CM_ "IMPORT _honda_common.dbc";
CM_ "IMPORT _nidec_common.dbc";
CM_ "IMPORT _steering_sensors_b.dbc";
CM_ "IMPORT _steering_control_a.dbc";

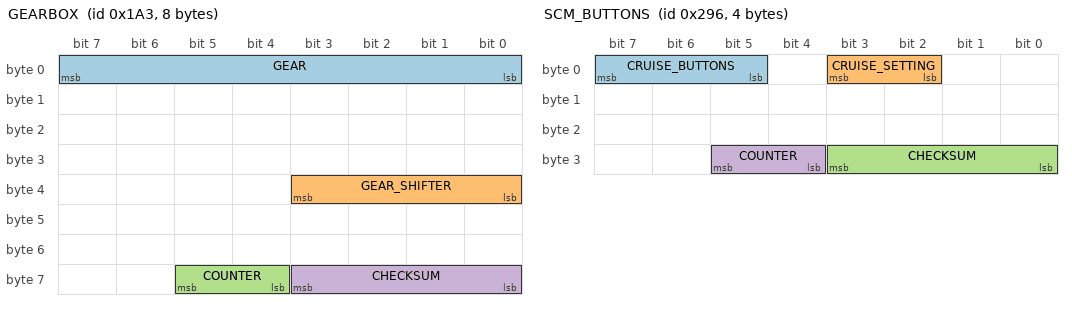
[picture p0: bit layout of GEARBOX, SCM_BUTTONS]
BO_ 419 GEARBOX: 8 PCM
 SG_ GEAR : 7|8@0+ (1,0) [0|256] "" EON
 SG_ GEAR_SHIFTER : 35|4@0+ (1,0) [0|15] "" EON
 SG_ COUNTER : 61|2@0+ (1,0) [0|3] "" EON
 SG_ CHECKSUM : 59|4@0+ (1,0) [0|3] "" EON

BO_ 662 SCM_BUTTONS: 4 SCM
 SG_ CRUISE_BUTTONS : 7|3@0+ (1,0) [0|7] "" EON
 SG_ CRUISE_SETTING : 3|2@0+ (1,0) [0|3] "" EON
 SG_ CHECKSUM : 27|4@0+ (1,0) [0|3] "" EON
 SG_ COUNTER : 29|2@0+ (1,0) [0|3] "" EON

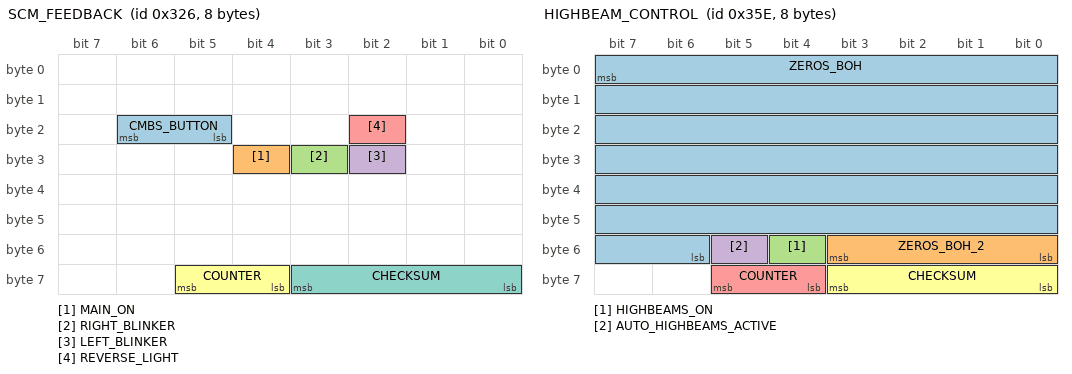
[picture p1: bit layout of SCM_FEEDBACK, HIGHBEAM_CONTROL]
BO_ 806 SCM_FEEDBACK: 8 SCM
 SG_ CMBS_BUTTON : 22|2@0+ (1,0) [0|3] "" EON
 SG_ MAIN_ON : 28|1@0+ (1,0) [0|1] "" EON
 SG_ RIGHT_BLINKER : 27|1@0+ (1,0) [0|1] "" EON
 SG_ LEFT_BLINKER : 26|1@0+ (1,0) [0|1] "" EON
 SG_ REVERSE_LIGHT : 18|1@0+ (1,0) [0|1] "" EON
 SG_ COUNTER : 61|2@0+ (1,0) [0|3] "" EON
 SG_ CHECKSUM : 59|4@0+ (1,0) [0|3] "" EON

BO_ 862 HIGHBEAM_CONTROL: 8 ADAS
 SG_ ZEROS_BOH : 7|50@0+ (1,0) [0|127] "" BDY
 SG_ ZEROS_BOH_2 : 48|4@1+ (1,0) [0|15] "" XXX
 SG_ HIGHBEAMS_ON : 52|1@0+ (1,0) [0|1] "" XXX
 SG_ AUTO_HIGHBEAMS_ACTIVE : 53|1@0+ (1,0) [0|1] "" XXX
 SG_ COUNTER : 61|2@0+ (1,0) [0|3] "" XXX
 SG_ CHECKSUM : 59|4@0+ (1,0) [0|15] "" XXX

CM_ SG_ 419 GEAR "10 = reverse, 11 = transition";
CM_ SG_ 780 CRUISE_SPEED "255 = no speed";
CM_ SG_ 806 REVERSE_LIGHT "Might be reverse gear selected and not the lights";

VAL_ 419 GEAR_SHIFTER 10 "S" 4 "D" 3 "N" 2 "R" 1 "P" ;
VAL_ 662 CRUISE_BUTTONS 7 "tbd" 6 "tbd" 5 "tbd" 4 "accel_res" 3 "decel_set" 2 "cancel" 1 "main" 0 "none" ;
VAL_ 662 CRUISE_SETTING 3 "distance_adj" 2 "tbd" 1 "lkas_button" 0 "none" ;
VAL_ 780 HUD_LEAD 3 "no_car" 2 "solid_car" 1 "dashed_car" 0 "no_car" ;
VAL_ 806 CMBS_BUTTON 3 "pressed" 0 "released" ;
